# ATSAMD51N19A device description
Architecture: CORTEX-M4; Family: SAMD; Series: SAMD51
Registers are 32-bit, read-write, reset 0x0 unless marked. A register's access mark holds for its fields unless they carry their own. Offsets are from the block's base; [hi:lo] are bit positions; {n}, {i} and the like mark numbered series; 'fields as' and 'values as' point back to an identical list.

## WDT — Watchdog Timer
Instances: WDT 0x40002000
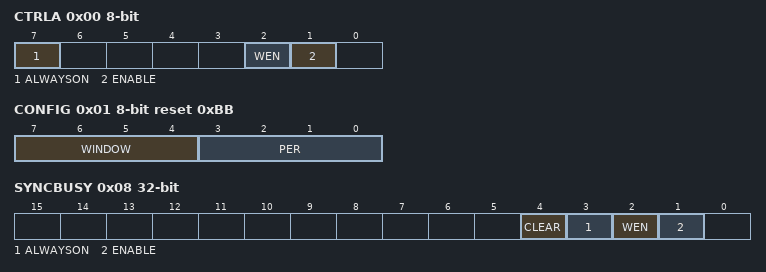
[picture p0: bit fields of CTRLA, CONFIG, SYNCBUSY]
0x00 CTRLA 8-bit (WSYNC) — Control
  [7] ALWAYSON
  [2] WEN — Watchdog Timer Window Mode Enable
  [1] ENABLE
0x01 CONFIG 8-bit reset 0xBB — Configuration
  [7:4] WINDOW — Window Mode Time-Out Period
    0=CYC8 (8 clock cycles); 1=CYC16 (16 clock cycles); 2=CYC32 (32 clock cycles); 3=CYC64 (64 clock cycles); 4=CYC128 (128 clock cycles); 5=CYC256 (256 clock cycles); 6=CYC512 (512 clock cycles); 7=CYC1024 (1024 clock cycles); 8=CYC2048 (2048 clock cycles); 9=CYC4096 (4096 clock cycles); 10=CYC8192 (8192 clock cycles); 11=CYC16384 (16384 clock cycles)
  [3:0] PER — Time-Out Period
    values as WINDOW
0x02 EWCTRL 8-bit reset 0xB — Early Warning Interrupt Control
  [3:0] EWOFFSET — Early Warning Interrupt Time Offset
    values as CONFIG.WINDOW
0x04 INTENCLR 8-bit (atomic clear) — Interrupt Enable Clear
  [0] EW — Early Warning Interrupt Enable
0x05 INTENSET 8-bit (atomic set) — Interrupt Enable Set
  [0] EW — Early Warning Interrupt Enable
0x06 INTFLAG 8-bit (atomic clear) — Interrupt Flag Status and Clear
  [0] EW — Early Warning
0x08 SYNCBUSY ro — Synchronization Busy
  [4] CLEAR — Clear Synchronization Busy
  [3] ALWAYSON — Always-On Synchronization Busy
  [2] WEN — Window Enable Synchronization Busy
  [1] ENABLE — Enable Synchronization Busy
0x0C CLEAR 8-bit wo (WSYNC)
  [7:0] CLEAR — Watchdog Clear
    165=KEY (Clear Key)

## SysTick — System timer
Instances: SysTick 0xE000E010
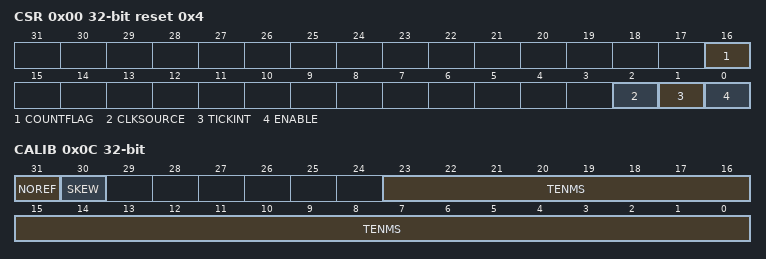
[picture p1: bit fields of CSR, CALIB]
0x00 CSR access not given reset 0x4 — SysTick Control and Status Register
  [16] COUNTFLAG
  [2] CLKSOURCE
    0=external clock; 1=processor clock
  [1] TICKINT
    0=counting down to 0 does not assert the SysTick exception request; 1=counting down to 0 asserts the SysTick exception request
  [0] ENABLE
    0=counter disabled; 1=counter enabled
0x04 RVR access not given — SysTick Reload Value Register
  [23:0] RELOAD — Value to load into the SysTick Current Value Register when the counter reaches 0
0x08 CVR access not given — SysTick Current Value Register
  [23:0] CURRENT — Current value at the time the register is accessed
0x0C CALIB access not given — SysTick Calibration Value Register
  [31] NOREF
    0=The reference clock is provided; 1=The reference clock is not provided
  [30] SKEW
    0=10ms calibration value is exact; 1=10ms calibration value is inexact, because of the clock frequency
  [23:0] TENMS — Reload value to use for 10ms timing

## NVIC — Nested Vectored Interrupt Controller
Instances: NVIC 0xE000E100
{0x0+4i} NVICISER{i} access not given (i=0..3) — Interrupt Set Enable Register n
  [31:0] SETENA — Interrupt set enable bits
{0x80+4i} NVICICER{i} access not given (i=0..3) — Interrupt Clear Enable Register n
  [31:0] CLRENA — Interrupt clear-enable bits
{0x100+4i} NVICISPR{i} access not given (i=0..3) — Interrupt Set Pending Register n
  [31:0] SETPEND — Interrupt set-pending bits
{0x180+4i} NVICICPR{i} access not given (i=0..3) — Interrupt Clear Pending Register n
  [31:0] CLRPEND — Interrupt clear-pending bits
{0x200+4i} NVICIABR{i} access not given (i=0..3) — Interrupt Active bit Register n
  [31:0] ACTIVE — Interrupt active flags
{0x300+i} NVICIP{i} 8-bit access not given (i=0..105) — Interrupt Priority Register n
  [7:0] PRI{i} — Priority of interrupt {i}
0xE00 NVICSTIR access not given — Software Trigger Interrupt Register
  [8:0] INTID — Interrupt ID of the interrupt to trigger, in the range 0-239. For example, a value of 0x03 specifies interrupt IRQ3.

## MPU — Memory Protection Unit
Instances: MPU 0xE000ED90
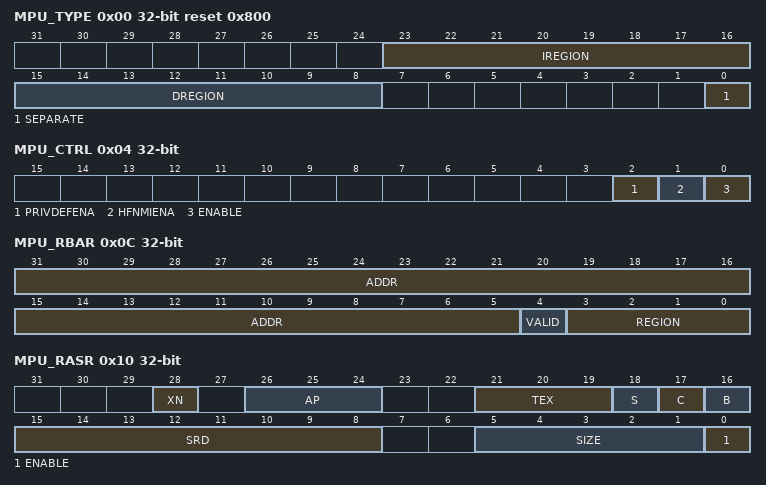
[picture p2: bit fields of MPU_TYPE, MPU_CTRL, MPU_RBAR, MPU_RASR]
0x00 MPU_TYPE ro reset 0x800
  [23:16] IREGION — Indicates the number of supported MPU data regions.
  [15:8] DREGION — Indicates the number of supported MPU instruction regions.
  [0] SEPARATE — Indicates support for unified or separate instruction and date memory maps.
0x04 MPU_CTRL — MPU Control Register
  [2] PRIVDEFENA — Enables privileged software access to the default memory map.
  [1] HFNMIENA — Enables the operation of MPU during hard fault, NMI, and FAULTMASK handlers.
  [0] ENABLE — Enables the MPU
0x08 MPU_RNR — MPU Region Number Register
  [7:0] REGION — Indicates the MPU region referenced by the MPU_RBAR and MPU_RASR registers.
0x0C MPU_RBAR — MPU Region Base Address Register
  [31:5] ADDR — Region base address field.
  [4] VALID — MPU Region Number valid bit.
  [3:0] REGION — MPU region field.
0x10 MPU_RASR — MPU Region Attribute and Size Register
  [28] XN — Instruction access disable bit.
  [26:24] AP — Access permission field.
  [21:19] TEX — MPU access permission attributes.
  [18] S — Shareable bit.
  [17] C — MPU access permission attributes.
  [16] B — MPU access permission attributes.
  [15:8] SRD — Subregion disable bits.
  [5:1] SIZE — Specifies the size of the MPU protection region.
  [0] ENABLE — Region enable bit.

## Notices in the file
Copyright (c) 2017 Microchip Technology Inc.
SPDX-License-Identifier: Apache-2.0
Licensed under the Apache License, Version 2.0 (the "License"); you may
not use this file except in compliance with the License.
You may obtain a copy of the Licence at
http://www.apache.org/licenses/LICENSE-2.0
Unless required by applicable law or agreed to in writing, software
distributed under the License is distributed on an AS IS BASIS, WITHOUT
WARRANTIES OR CONDITIONS OF ANY KIND, either express or implied.
See the License for the specific language governing permissions and
limitations under the License.
